# A31G324 register map
Vendor: ABOV Semiconductor Co., Ltd.; Series: A31G324; File version: 1.0
CPU: CM0PLUS r0p1, little endian, no MPU, no FPU, VTOR, 2 interrupt priority bits
Registers are 32-bit, read-write, reset 0x0 unless marked. A register's access mark holds for its fields unless they carry their own. Offsets are from the block's base; [hi:lo] are bit positions; {n}, {i} and the like mark numbered series.

## SPI20 — Serial Peripheral Interface
Base 0x40004C00
Same registers: SPI21 0x40004D00
0x00 TDR wo — SPI2 n Transmit Data Register
  [16:0] TDR — Transmit Data Bit
0x00 RDR ro — SPI n Received Data Register
  [16:0] RDR — Received Data Bit
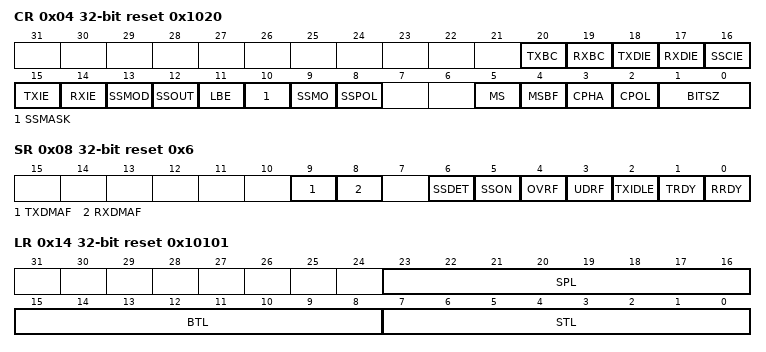
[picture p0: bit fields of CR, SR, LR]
0x04 CR reset 0x1020 — SPI Control Register
  [20] TXBC — Tx buffer clear bit
  [19] RXBC — Rx buffer clear bit
  [18] TXDIE — DMA Tx Done Interrupt Enable bit.
  [17] RXDIE — DMA Rx Done Interrupt Enable bit.
  [16] SSCIE — SS Edge Change Interrupt Enable bit.
  [15] TXIE — Transmit Interrupt Enable bit.
  [14] RXIE — Receive Interrupt Enable bit.
  [13] SSMOD — SS Auto/Manual output select bit.
  [12] SSOUT — SS output signal select bit.
  [11] LBE — Loop-back mode select bit in master mode.
  [10] SSMASK — SS signal masking bit in slave mode.
  [9] SSMO — SS output signal select bit.
  [8] SSPOL — SS output Polarity select bit.
  [5] MS — Master/Slave select bit.
  [4] MSBF — MSB/LSB Transmit select bit.
  [3] CPHA — SPI Clock Phase bit.
  [2] CPOL — SPI Clock Polarity bit.
  [1:0] BITSZ — Transmit/Receive Data Bits select bit.
0x08 SR reset 0x6 — SPI Status Register
  [9] TXDMAF — DMA Transmit Operation Complete flag.
  [8] RXDMAF — DMA Receive Operation Complete flag.
  [6] SSDET — The rising or falling edge of SS signal Detect flag.
  [5] SSON — SS signal Status flag.
  [4] OVRF — Receive Overrun Error flag.
  [3] UDRF — Transmit Underrun Error flag.
  [2] TXIDLE ro — Transmit/Receive Operation flag.
  [1] TRDY ro — Transmit buffer Empty flag.
  [0] RRDY ro — Receive buffer Ready flag.
0x0C BR reset 0xFFFF — SPI Baud Rate Register
  [15:0] BR — Baud rate setting bits.
0x10 EN — SPI Enable Register
  [0] ENABLE — SPI Enable bit
0x14 LR reset 0x10101 — SPI Delay Length Register
  [23:16] SPL — StoPLength value
  [15:8] BTL — BursTLength value
  [7:0] STL — STart Length value

## ADC — 12-BIT A/D CONVERTER
Base 0x40003000
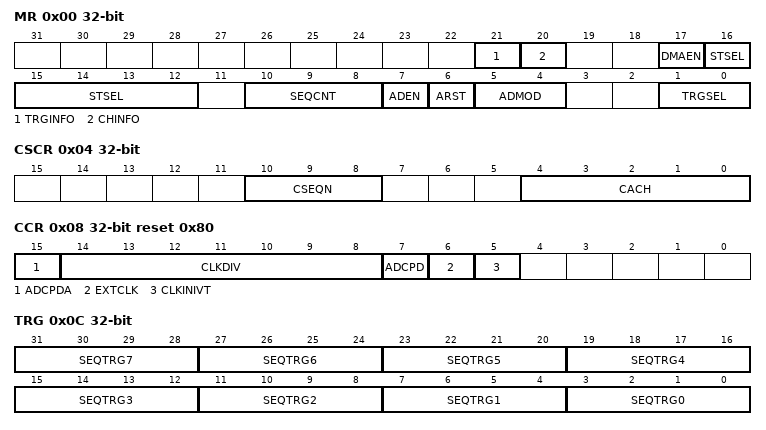
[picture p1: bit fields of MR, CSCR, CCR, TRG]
0x00 MR (reset mask 0x33F7F0) — A/D Converter Mode Register
  [21] TRGINFO — Trigger information option (In external trigger mode)
  [20] CHINFO — Channel information option
  [17] DMAEN — DMA Enable bit (Must be set When ADCEN = 1)
  [16:12] STSEL — Sampling Time Selection
  [10:8] SEQCNT — Number of coversion in a sequence
  [7] ADEN — ADC Enable bit
  [6] ARST — After sequence finish, restart bit
  [5:4] ADMOD — ADC Mode Selection bit
  [1:0] TRGSEL — Trigger Selection bit
0x04 CSCR — A/D Converter Current Sequence/Channel Register
  [10:8] CSEQN — Current Sequence Number
  [4:0] CACH ro — Current Active Channel
0x08 CCR reset 0x80 — A/D Converter Clock Register
  [15] ADCPDA — ADC R DAC disable to save power Don't set '1' here(it's optional bit)
  [14:8] CLKDIV — ADC clock division value bit(When EXTCLK is 0, CLKDIV Enable)
  [7] ADCPD — ADC Deep sleep
  [6] EXTCLK — ADC External Clock Selection bit
  [5] CLKINIVT — Divide Clock Inversion (Option bit)
0x0C TRG — A/D Converter Trigger Selection Register
  [4n+3:4n] SEQTRG{n} (n=2..7) — {n+1}th Sequence Trigger Source
  [7:4] SEQTRG1 — 2nd Sequence Trigger Source
  [3:0] SEQTRG0 — 1st Sequence Trigger Source
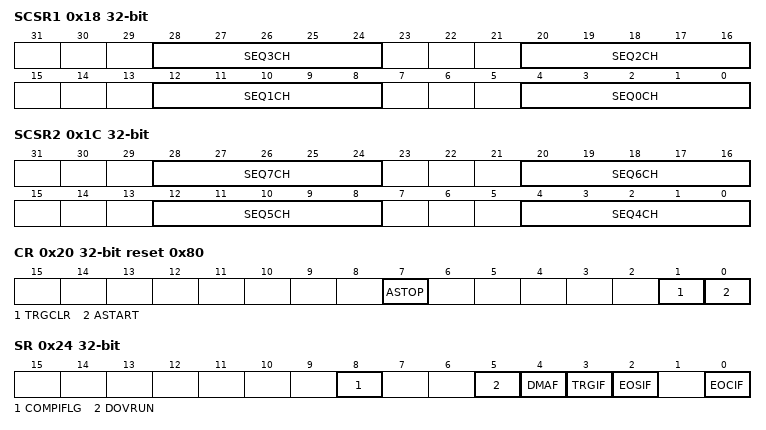
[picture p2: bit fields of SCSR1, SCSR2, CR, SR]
0x18 SCSR1 — A/D Converter Channel Selection 1 Register
  [28:24] SEQ3CH — 4th Conversion Sequence Channel Selection
  [20:16] SEQ2CH — 3th Conversion Sequence Channel Selection
  [12:8] SEQ1CH — 2nd Conversion Sequence Channel Selection
  [4:0] SEQ0CH — 1st Conversion Sequence Channel Selection
0x1C SCSR2 — A/D Converter Channel Selection 2 Register
  [8n-28:8n-32] SEQ{n}CH (n=4..7) — {n+1}th Conversion Sequence Channel Selection
0x20 CR reset 0x80 — A/D Converter Control Register
  [7] ASTOP wo — ADC STOP bit
  [1] TRGCLR — ADC all trigger flags cleared option
  [0] ASTART — ADC START bit
0x24 SR — A/D Converter State Register
  [8] COMPIFLG — Compare Interrupt Flag bit
  [5] DOVRUN ro — DMA Overrun Flag(Not Interrupt)
  [4] DMAF ro — DMA Done Received Flag(DMA transfer is completed)
  [3] TRGIF — ADC Trigger Interrupt Flag
  [2] EOSIF — Sequence End Interrupt Flag
  [0] EOCIF — Sequence Conversion End Interrupt Flag
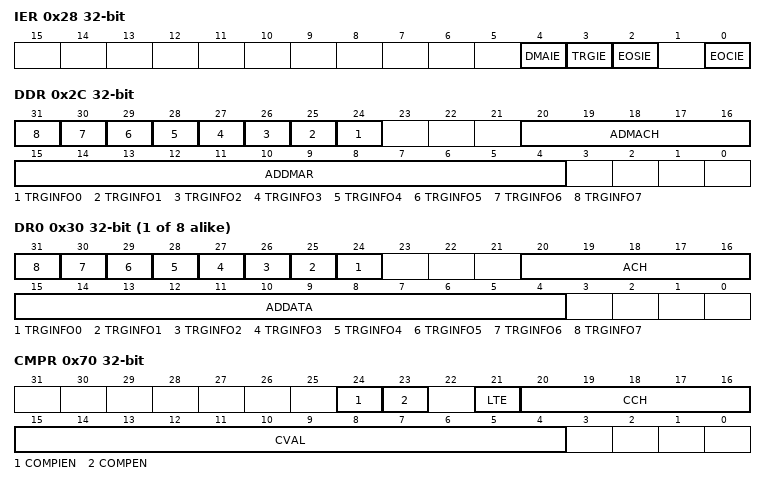
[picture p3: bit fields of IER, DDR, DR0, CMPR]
0x28 IER — A/D Converter Interrupt Enable Register
  [4] DMAIE — DMA Done Interrupt Enable
  [3] TRGIE — ADC Trigger Conversion Interrupt Enable
  [2] EOSIE — ADC Sequence Conversion Interrupt Enable
  [0] EOCIE — ADC Single Conversion
0x2C DDR ro — A/D Converter DMA Data Register
  [n+24] TRGINFO{n} (n=0..7) — ADC Trigger Information(ADC Trigger Information is Trigger source captured at EOC time.) Must be enable TRGINFO function of ADC_MR Register
  [20:16] ADMACH — DMA ADC Channel Indicator
  [15:4] ADDMAR — DMA ADC Conversion Result Data(12-bit)
{0x30+4i} DR{i} ro (i=0..7) — A/D Converter Sequence 0~7 Data Register
  [n+24] TRGINFO{n} (n=0..7) — ADC Trigger Information(ADC Trigger Information is Trigger source captured at EOC time.) Must be enable TRGINFO function of ADC_MR Register
  [20:16] ACH — ADC Channel Information
  [15:4] ADDATA — ADC Input data
0x70 CMPR — A/D Converter Channel Compare Register
  [24] COMPIEN — Compare Interrupt Enable bit
  [23] COMPEN — Compare Operation Enable bit
  [21] LTE — AD Conversion Value Output Timing Setting
  [20:16] CCH — Compare Channel
  [15:4] CVAL — Compare Value Bit
